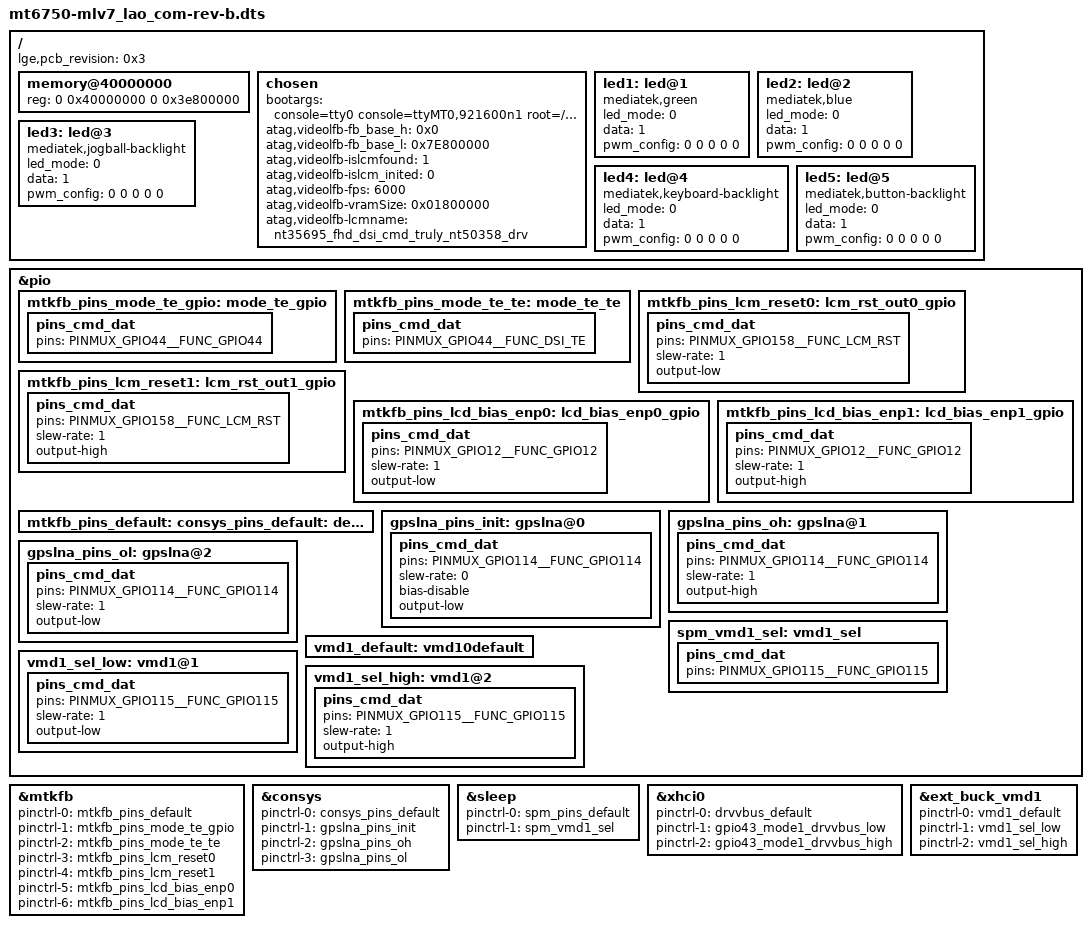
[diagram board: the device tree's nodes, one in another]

/dts-v1/;

#include "mt6755.dtsi"
#include "mt6750-mlv7_lao_com-cust.dtsi"

#include "mt6750-mlv7_lao_com-power.dtsi"
#include "mt6750-mlv7_lao_com-panel.dtsi"
#include "mt6750-mlv7_lao_com-touch.dtsi"
#include "mt6750-mlv7_lao_com-sensor.dtsi"
#include "mt6750-mlv7_lao_com-misc.dtsi"
#include "mt6750-mlv7_lao_com-sound.dtsi"
/* #include "mt6750-mlv7_lao_com-nfc.dtsi" */
#include "mt6750-mlv7_lao_com-common.dtsi"
#include "mt6750-mlv7_lao_com-usb.dtsi"
#include "mt6750-mlv7_lao_com-camera.dtsi"

/ {
	/*
	typedef enum {
		HW_REV_0 = 0,
		HW_REV_0_1,
		HW_REV_A,
		HW_REV_B,
		HW_REV_C,
		HW_REV_1_0,
		HW_REV_1_1,
		HW_REV_MAX
	} rev_type;
	*/
	lge,pcb_revision = <0x3>; // rev_b
};

/ {
	memory@40000000 {
		device_type = "memory";
		reg = <0 0x40000000 0 0x3e800000>;
	};
	/* chosen */
	chosen {
		bootargs = "console=tty0 console=ttyMT0,921600n1 root=/dev/ram initrd=0x44000000,0x4B434E loglevel=8";

		/* fpga may has no lk, we need to specify display info here */
		/* fb buffer is reserved using this dts by memory node above */
		atag,videolfb-fb_base_h = <0x0>;
		atag,videolfb-fb_base_l = <0x7E800000>;
		atag,videolfb-islcmfound = <1>;
		/* because no lk, so lcm is not inited */
		atag,videolfb-islcm_inited = <0>;
		atag,videolfb-fps= <6000>;
		atag,videolfb-vramSize= <0x01800000>;
		atag,videolfb-lcmname= "nt35695_fhd_dsi_cmd_truly_nt50358_drv";
	};

	led1:led@1 {
		compatible = "mediatek,green";
		led_mode = <0>;
		data = <1>;
		pwm_config = <0 0 0 0 0>;
	};
	led2:led@2 {
		compatible = "mediatek,blue";
		led_mode = <0>;
		data = <1>;
		pwm_config = <0 0 0 0 0>;
	};
	led3:led@3 {
		compatible = "mediatek,jogball-backlight";
		led_mode = <0>;
		data = <1>;
		pwm_config = <0 0 0 0 0>;
	};
	led4:led@4 {
		compatible = "mediatek,keyboard-backlight";
		led_mode = <0>;
		data = <1>;
		pwm_config = <0 0 0 0 0>;
	};
	led5:led@5 {
		compatible = "mediatek,button-backlight";
		led_mode = <0>;
		data = <1>;
		pwm_config = <0 0 0 0 0>;
	};
};

/* DISPSYS GPIO standardization */
&pio {

	mtkfb_pins_mode_te_gpio: mode_te_gpio {
		pins_cmd_dat {
			pins = <PINMUX_GPIO44__FUNC_GPIO44>;
		};
	};

	mtkfb_pins_mode_te_te: mode_te_te {
		pins_cmd_dat {
			pins = <PINMUX_GPIO44__FUNC_DSI_TE>;
		};
	};

	mtkfb_pins_lcm_reset0: lcm_rst_out0_gpio {
		pins_cmd_dat {
			pins = <PINMUX_GPIO158__FUNC_LCM_RST>;
			slew-rate = <1>;
			output-low;
		};
	};

	mtkfb_pins_lcm_reset1: lcm_rst_out1_gpio {
		pins_cmd_dat {
			pins = <PINMUX_GPIO158__FUNC_LCM_RST>;
			slew-rate = <1>;
			output-high;
		};
	};

	mtkfb_pins_lcd_bias_enp0: lcd_bias_enp0_gpio {
		pins_cmd_dat {
			pins = <PINMUX_GPIO12__FUNC_GPIO12>;
			slew-rate = <1>;
			output-low;
		};
	};

	mtkfb_pins_lcd_bias_enp1: lcd_bias_enp1_gpio {
		pins_cmd_dat {
			pins = <PINMUX_GPIO12__FUNC_GPIO12>;
			slew-rate = <1>;
			output-high;
		};
	};

	mtkfb_pins_default: default {
	};
};

&mtkfb {
	pinctrl-names = "default", "mode_te_gpio", "mode_te_te", "lcm_rst_out0_gpio",
	"lcm_rst_out1_gpio", "lcd_bias_enp0_gpio", "lcd_bias_enp1_gpio";
	pinctrl-0 = <&mtkfb_pins_default>;
	pinctrl-1 = <&mtkfb_pins_mode_te_gpio>;
	pinctrl-2 = <&mtkfb_pins_mode_te_te>;
	pinctrl-3 = <&mtkfb_pins_lcm_reset0>;
	pinctrl-4 = <&mtkfb_pins_lcm_reset1>;
	pinctrl-5 = <&mtkfb_pins_lcd_bias_enp0>;
	pinctrl-6 = <&mtkfb_pins_lcd_bias_enp1>;
	status = "okay";
};/* DISPSYS GPIO standardization end */

/* CONSYS GPIO standardization */
&pio {
	consys_pins_default: default {
	};

	gpslna_pins_init: gpslna@0 {
		pins_cmd_dat {
			pins = <PINMUX_GPIO114__FUNC_GPIO114>;
			slew-rate = <0>;
			bias-disable;
			output-low;
		};
	};

	gpslna_pins_oh: gpslna@1 {
		pins_cmd_dat {
			pins = <PINMUX_GPIO114__FUNC_GPIO114>;
			slew-rate = <1>;
			output-high;
		};
	};

	gpslna_pins_ol: gpslna@2 {
		pins_cmd_dat {
			pins = <PINMUX_GPIO114__FUNC_GPIO114>;
			slew-rate = <1>;
			output-low;
		};
	};
};

&consys {
	pinctrl-names = "default", "gps_lna_state_init", "gps_lna_state_oh", "gps_lna_state_ol";
	pinctrl-0 = <&consys_pins_default>;
	pinctrl-1 = <&gpslna_pins_init>;
	pinctrl-2 = <&gpslna_pins_oh>;
	pinctrl-3 = <&gpslna_pins_ol>;
	status = "okay";
};
/* CONSYS end */

/* SPM GPIO standardization */
&pio {
	spm_pins_default: default {
	};

	spm_vmd1_sel: vmd1_sel {
		pins_cmd_dat {
			pins = <PINMUX_GPIO115__FUNC_GPIO115>;
		};
	};

};

&sleep{
	pinctrl-names = "default", "vmd1_sel";
	pinctrl-0 = <&spm_pins_default>;
	pinctrl-1 = <&spm_vmd1_sel>;
	status = "okay";
};
/* SPM end */


&xhci0 {
	pinctrl-names = "drvvbus_default", "drvvbus_low", "drvvbus_high";
	pinctrl-0 = <&drvvbus_default>;
	pinctrl-1 = <&gpio43_mode1_drvvbus_low>;
	pinctrl-2 = <&gpio43_mode1_drvvbus_high>;
	status = "okay";
};

&ext_buck_vmd1 {
	pinctrl-names = "default", "vmd1_sel_low", "vmd1_sel_high";

	pinctrl-0 = <&vmd1_default>;
	pinctrl-1 = <&vmd1_sel_low>;
	pinctrl-2 = <&vmd1_sel_high>;
};

&pio {
	vmd1_default: vmd10default {
	};

	vmd1_sel_low: vmd1@1 {
		pins_cmd_dat {
			pins = <PINMUX_GPIO115__FUNC_GPIO115>;
			slew-rate = <1>;
			output-low;
		};
	};

	vmd1_sel_high: vmd1@2 {
		pins_cmd_dat {
			pins = <PINMUX_GPIO115__FUNC_GPIO115>;
			slew-rate = <1>;
			output-high;
		};
	};
};
